AUTOSAR XML (schema 4-0-3)
standard types defined: Std_ReturnType
package /Csm/CompuMethods
  compu method Csm_ConfigIdTypeValues: 0=HaeAdvSeedKey_L9_Id, 1=HaeSha1_Id, 2=HaeSha256_Id, 0=HaeHmacSha256Generate_Id, 0=HaeHmacSha256Verify_Id, 0=HaeHsmPseudoRandomGenerate_L9_Id, 2=HaePseudoRandomGenerate_Id, 1=HaePseudoRandomGenerate_L9_Id, 1=HaePseudoRandomSeed_Id, 0=HaePseudoRandomSeed_L9_Id, 0=HaePkcs1V15Sha256Generate_Id, 0=HaeAesEcbDecrypt_Id, 0=HaeAesEcbEncrypt_Id, 0=HaeAesCbcDecrypt_Id, 1=HaeAesCtrDecrypt_Id, 0=HaeAesCbcEncrypt_Id, 1=HaeAesCtrEncrypt_Id
package /Csm/ImplementationDataTypes
  impl type Csm_AlignType: implementation-data-type=uint8
  impl type Csm_ConfigIdType: implementation-data-type=uint16
  impl type Csm_VerifyResultType: compu {0=CSM_E_VER_OK, 1=CSM_E_VER_NOT_OK}, implementation-data-type=uint8
package /Csm/ArrayTypes
  20 x impl type, all with category=ARRAY:
    HashDataBuffer
      element HashDataBufferElement: array-size=8, array-size-semantics=FIXED-SIZE, implementation-data-type=uint8
    HashResultBuffer
      element HashResultBufferElement: array-size=8, array-size-semantics=FIXED-SIZE, implementation-data-type=uint8
    MacGenerateDataBuffer
      element MacGenerateDataBufferElement: array-size=1, array-size-semantics=FIXED-SIZE, implementation-data-type=uint8
    MacGenerateResultBuffer
      element MacGenerateResultBufferElement: array-size=32, array-size-semantics=FIXED-SIZE, implementation-data-type=uint8
    MacVerifyCompareBuffer
      element MacVerifyCompareBufferElement: array-size=32, array-size-semantics=FIXED-SIZE, implementation-data-type=uint8
    MacVerifyDataBuffer
      element MacVerifyDataBufferElement: array-size=1, array-size-semantics=FIXED-SIZE, implementation-data-type=uint8
    RandomGenerateResultBuffer
      element RandomGenerateResultBufferElement: array-size=8, array-size-semantics=FIXED-SIZE, implementation-data-type=uint8
    RandomSeedDataBuffer
      element RandomSeedDataBufferElement: array-size=16, array-size-semantics=FIXED-SIZE, implementation-data-type=uint8
    SignatureGenerateDataBuffer
      element SignatureGenerateDataBufferElement: array-size=1, array-size-semantics=FIXED-SIZE, implementation-data-type=uint8
    SignatureGenerateResultBuffer
      element SignatureGenerateResultBufferElement: array-size=256, array-size-semantics=FIXED-SIZE, implementation-data-type=uint8
    SymBlockDecryptDataBuffer
      element SymBlockDecryptDataBufferElement: array-size=1, array-size-semantics=FIXED-SIZE, implementation-data-type=uint8
    SymBlockDecryptResultBuffer
      element SymBlockDecryptResultBufferElement: array-size=1, array-size-semantics=FIXED-SIZE, implementation-data-type=uint8
    SymBlockEncryptDataBuffer
      element SymBlockEncryptDataBufferElement: array-size=1, array-size-semantics=FIXED-SIZE, implementation-data-type=uint8
    SymBlockEncryptResultBuffer
      element SymBlockEncryptResultBufferElement: array-size=1, array-size-semantics=FIXED-SIZE, implementation-data-type=uint8
    SymDecryptDataBuffer
      element SymDecryptDataBufferElement: array-size=1, array-size-semantics=FIXED-SIZE, implementation-data-type=uint8
    SymDecryptInitVectorBuffer
      element SymDecryptInitVectorBufferElement: array-size=16, array-size-semantics=FIXED-SIZE, implementation-data-type=uint8
    SymDecryptResultBuffer
      element SymDecryptResultBufferElement: array-size=1, array-size-semantics=FIXED-SIZE, implementation-data-type=uint8
    SymEncryptDataBuffer
      element SymEncryptDataBufferElement: array-size=1, array-size-semantics=FIXED-SIZE, implementation-data-type=uint8
    SymEncryptInitVectorBuffer
      element SymEncryptInitVectorBufferElement: array-size=16, array-size-semantics=FIXED-SIZE, implementation-data-type=uint8
    SymEncryptResultBuffer
      element SymEncryptResultBufferElement: array-size=1, array-size-semantics=FIXED-SIZE, implementation-data-type=uint8
package /Csm/RecordTypes
  impl type Csm_AsymPrivateKeyType: category=STRUCTURE
    element length: implementation-data-type=uint32
    element data: category=ARRAY, array-size-semantics=FIXED-SIZE
      element data_element: array-size=512, array-size-semantics=FIXED-SIZE, implementation-data-type=Csm_AlignType
  impl type Csm_SymKeyType: category=STRUCTURE
    element length: implementation-data-type=uint32
    element data: category=ARRAY, array-size-semantics=FIXED-SIZE
      element data_element: array-size=16, array-size-semantics=FIXED-SIZE, implementation-data-type=Csm_AlignType
package /Csm/ClientServerInterfaces
  11 x client server interface, all with is-service=true, service-kind=CRYPTO-SERVICE-MANAGER:
    CsmHash
      operation HashStart: possible-error=[CsmHash/E_NOT_OK, CsmHash/CSM_E_BUSY]
      operation HashUpdate: possible-error=[CsmHash/E_NOT_OK, CsmHash/CSM_E_BUSY]
        arg dataBuffer: type=HashDataBuffer, direction=IN
        arg dataLength: type=uint32, direction=IN
      operation HashFinish: possible-error=[CsmHash/E_NOT_OK, CsmHash/CSM_E_BUSY, CsmHash/CSM_E_SMALL_BUFFER]
        arg resultBuffer: type=HashResultBuffer, direction=OUT
        arg resultLength: type=uint32, direction=INOUT
        arg TruncationIsAllowed: type=boolean, direction=IN
      error E_NOT_OK: error-code=1
      error CSM_E_BUSY: error-code=2
      error CSM_E_SMALL_BUFFER: error-code=3
    CsmMacGenerate
      operation MacGenerateStart: possible-error=[CsmMacGenerate/E_NOT_OK, CsmMacGenerate/CSM_E_BUSY]
        arg key: type=Csm_SymKeyType, direction=IN
      operation MacGenerateUpdate: possible-error=[CsmMacGenerate/E_NOT_OK, CsmMacGenerate/CSM_E_BUSY]
        arg dataBuffer: type=MacGenerateDataBuffer, direction=IN
        arg dataLength: type=uint32, direction=IN
      operation MacGenerateFinish: possible-error=[CsmMacGenerate/E_NOT_OK, CsmMacGenerate/CSM_E_BUSY, CsmMacGenerate/CSM_E_SMALL_BUFFER]
        arg resultBuffer: type=MacGenerateResultBuffer, direction=OUT
        arg resultLength: type=uint32, direction=INOUT
        arg TruncationIsAllowed: type=boolean, direction=IN
      error E_NOT_OK: error-code=1
      error CSM_E_BUSY: error-code=2
      error CSM_E_SMALL_BUFFER: error-code=3
    CsmMacVerify
      operation MacVerifyStart: possible-error=[CsmMacVerify/E_NOT_OK, CsmMacVerify/CSM_E_BUSY]
        arg key: type=Csm_SymKeyType, direction=IN
      operation MacVerifyUpdate: possible-error=[CsmMacVerify/E_NOT_OK, CsmMacVerify/CSM_E_BUSY]
        arg dataBuffer: type=MacVerifyDataBuffer, direction=IN
        arg dataLength: type=uint32, direction=IN
      operation MacVerifyFinish: possible-error=[CsmMacVerify/E_NOT_OK, CsmMacVerify/CSM_E_BUSY]
        arg MacBuffer: type=MacVerifyCompareBuffer, direction=IN
        arg MacLength: type=uint32, direction=IN
        arg resultBuffer: type=Csm_VerifyResultType, direction=OUT
      error E_NOT_OK: error-code=1
      error CSM_E_BUSY: error-code=2
    CsmRandomGenerate
      operation RandomGenerate: possible-error=[CsmRandomGenerate/E_NOT_OK, CsmRandomGenerate/CSM_E_BUSY, CSM_E_ENTROPY_EXHAUSTION]
        arg resultBuffer: type=RandomGenerateResultBuffer, direction=OUT
        arg resultLength: type=uint32, direction=IN
      error E_NOT_OK: error-code=1
      error CSM_E_BUSY: error-code=2
      error CSM_E_ENTROPY_EXHAUSTION: error-code=4
    CsmRandomSeed
      operation RandomSeedStart: possible-error=[CsmRandomSeed/E_NOT_OK, CsmRandomSeed/CSM_E_BUSY]
      operation RandomSeedUpdate: possible-error=[CsmRandomSeed/E_NOT_OK, CsmRandomSeed/CSM_E_BUSY]
        arg seedBuffer: type=RandomSeedDataBuffer, direction=IN
        arg seedLength: type=uint32, direction=IN
      operation RandomSeedFinish: possible-error=[CsmRandomSeed/E_NOT_OK, CsmRandomSeed/CSM_E_BUSY]
      error E_NOT_OK: error-code=1
      error CSM_E_BUSY: error-code=2
    CsmSignatureGenerate
      operation SignatureGenerateStart: possible-error=[CsmSignatureGenerate/E_NOT_OK, CsmSignatureGenerate/CSM_E_BUSY]
        arg key: type=Csm_AsymPrivateKeyType, direction=IN
      operation SignatureGenerateUpdate: possible-error=[CsmSignatureGenerate/E_NOT_OK, CsmSignatureGenerate/CSM_E_BUSY, CsmSignatureGenerate/CSM_E_SMALL_BUFFER]
        arg dataBuffer: type=SignatureGenerateDataBuffer, direction=IN
        arg dataLength: type=uint32, direction=IN
      operation SignatureGenerateFinish: possible-error=[CsmSignatureGenerate/E_NOT_OK, CsmSignatureGenerate/CSM_E_BUSY, CsmSignatureGenerate/CSM_E_SMALL_BUFFER]
        arg resultBuffer: type=SignatureGenerateResultBuffer, direction=OUT
        arg resultLength: type=uint32, direction=INOUT
      error E_NOT_OK: error-code=1
      error CSM_E_BUSY: error-code=2
      error CSM_E_SMALL_BUFFER: error-code=3
    CsmSymBlockDecrypt
      operation SymBlockDecryptStart: possible-error=[CsmSymBlockDecrypt/E_NOT_OK, CsmSymBlockDecrypt/CSM_E_BUSY]
        arg key: type=Csm_SymKeyType, direction=IN
      operation SymBlockDecryptUpdate: possible-error=[CsmSymBlockDecrypt/E_NOT_OK, CsmSymBlockDecrypt/CSM_E_BUSY, CsmSymBlockDecrypt/CSM_E_SMALL_BUFFER]
        4 x arg:
          cipherTextBuffer: type=SymBlockDecryptDataBuffer, direction=IN
          cipherTextLength: type=uint32, direction=IN
          plainTextBuffer: type=SymBlockDecryptResultBuffer, direction=OUT
          plainTextLength: type=uint32, direction=INOUT
      operation SymBlockDecryptFinish: possible-error=[CsmSymBlockDecrypt/E_NOT_OK, CsmSymBlockDecrypt/CSM_E_BUSY]
      error E_NOT_OK: error-code=1
      error CSM_E_BUSY: error-code=2
      error CSM_E_SMALL_BUFFER: error-code=3
    CsmSymBlockEncrypt
      operation SymBlockEncryptStart: possible-error=[CsmSymBlockEncrypt/E_NOT_OK, CsmSymBlockEncrypt/CSM_E_BUSY]
        arg key: type=Csm_SymKeyType, direction=IN
      operation SymBlockEncryptUpdate: possible-error=[CsmSymBlockEncrypt/E_NOT_OK, CsmSymBlockEncrypt/CSM_E_BUSY, CsmSymBlockEncrypt/CSM_E_SMALL_BUFFER]
        4 x arg:
          plainTextBuffer: type=SymBlockEncryptDataBuffer, direction=IN
          plainTextLength: type=uint32, direction=IN
          cipherTextBuffer: type=SymBlockEncryptResultBuffer, direction=OUT
          cipherTextLength: type=uint32, direction=INOUT
      operation SymBlockEncryptFinish: possible-error=[CsmSymBlockEncrypt/E_NOT_OK, CsmSymBlockEncrypt/CSM_E_BUSY]
      error E_NOT_OK: error-code=1
      error CSM_E_BUSY: error-code=2
      error CSM_E_SMALL_BUFFER: error-code=3
    CsmSymDecrypt
      operation SymDecryptStart: possible-error=[CsmSymDecrypt/E_NOT_OK, CsmSymDecrypt/CSM_E_BUSY]
        arg key: type=Csm_SymKeyType, direction=IN
        arg InitVectorBuffer: type=SymEncryptInitVectorBuffer, direction=IN
        arg InitVectorLength: type=uint32, direction=IN
      operation SymDecryptUpdate: possible-error=[CsmSymDecrypt/E_NOT_OK, CsmSymDecrypt/CSM_E_BUSY, CsmSymDecrypt/CSM_E_SMALL_BUFFER]
        4 x arg:
          cipherTextBuffer: type=SymDecryptDataBuffer, direction=IN
          cipherTextLength: type=uint32, direction=IN
          plainTextBuffer: type=SymDecryptResultBuffer, direction=OUT
          plainTextLength: type=uint32, direction=INOUT
      operation SymDecryptFinish: possible-error=[CsmSymDecrypt/E_NOT_OK, CsmSymDecrypt/CSM_E_BUSY, CsmSymDecrypt/CSM_E_SMALL_BUFFER]
        arg plainTextBuffer: type=SymDecryptResultBuffer, direction=OUT
        arg plainTextLength: type=uint32, direction=INOUT
      error E_NOT_OK: error-code=1
      error CSM_E_BUSY: error-code=2
      error CSM_E_SMALL_BUFFER: error-code=3
    CsmSymEncrypt
      operation SymEncryptStart: possible-error=[CsmSymEncrypt/E_NOT_OK, CsmSymEncrypt/CSM_E_BUSY]
        arg key: type=Csm_SymKeyType, direction=IN
        arg InitVectorBuffer: type=SymEncryptInitVectorBuffer, direction=IN
        arg InitVectorLength: type=uint32, direction=IN
      operation SymEncryptUpdate: possible-error=[CsmSymEncrypt/E_NOT_OK, CsmSymEncrypt/CSM_E_BUSY, CsmSymEncrypt/CSM_E_SMALL_BUFFER]
        4 x arg:
          plainTextBuffer: type=SymEncryptDataBuffer, direction=IN
          plainTextLength: type=uint32, direction=IN
          cipherTextBuffer: type=SymEncryptResultBuffer, direction=OUT
          cipherTextLength: type=uint32, direction=INOUT
      operation SymEncryptFinish: possible-error=[CsmSymEncrypt/E_NOT_OK, CsmSymEncrypt/CSM_E_BUSY, CsmSymEncrypt/CSM_E_SMALL_BUFFER]
        arg cipherTextBuffer: type=SymEncryptResultBuffer, direction=OUT
        arg cipherTextLength: type=uint32, direction=INOUT
      error E_NOT_OK: error-code=1
      error CSM_E_BUSY: error-code=2
      error CSM_E_SMALL_BUFFER: error-code=3
    CsmCallback
      operation JobFinished: possible-error=CsmCallback/E_NOT_OK
        arg retVal: type=Std_ReturnType, direction=IN
      error E_NOT_OK: error-code=1
package /Csm/ServiceSwComponentTypes
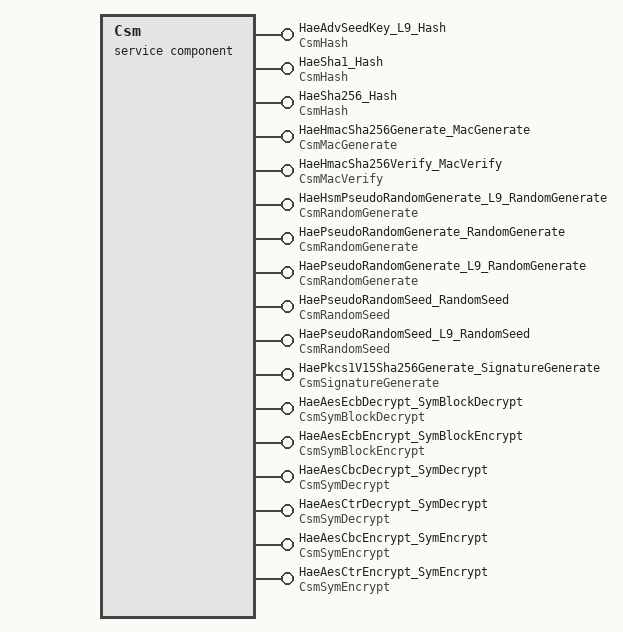
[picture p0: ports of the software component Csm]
  service sw component type Csm
    17 x provide port:
      HaeAdvSeedKey_L9_Hash: provided-interface=CsmHash
        provided-com-specs:
          operation=HashStart, queue-length=1
          operation=HashUpdate, queue-length=1
          operation=HashFinish, queue-length=1
      HaeSha1_Hash: provided-interface=CsmHash
        provided-com-specs:
          operation=HashStart, queue-length=1
          operation=HashUpdate, queue-length=1
          operation=HashFinish, queue-length=1
      HaeSha256_Hash: provided-interface=CsmHash
        provided-com-specs:
          operation=HashStart, queue-length=1
          operation=HashUpdate, queue-length=1
          operation=HashFinish, queue-length=1
      HaeHmacSha256Generate_MacGenerate: provided-interface=CsmMacGenerate
        provided-com-specs:
          operation=MacGenerateStart, queue-length=1
          operation=MacGenerateUpdate, queue-length=1
          operation=MacGenerateFinish, queue-length=1
      HaeHmacSha256Verify_MacVerify: provided-interface=CsmMacVerify
        provided-com-specs:
          operation=MacVerifyStart, queue-length=1
          operation=MacVerifyUpdate, queue-length=1
          operation=MacVerifyFinish, queue-length=1
      HaeHsmPseudoRandomGenerate_L9_RandomGenerate: server-com-spec{operation=RandomGenerate, queue-length=1}, provided-interface=CsmRandomGenerate
      HaePseudoRandomGenerate_RandomGenerate: server-com-spec{operation=RandomGenerate, queue-length=1}, provided-interface=CsmRandomGenerate
      HaePseudoRandomGenerate_L9_RandomGenerate: server-com-spec{operation=RandomGenerate, queue-length=1}, provided-interface=CsmRandomGenerate
      HaePseudoRandomSeed_RandomSeed: provided-interface=CsmRandomSeed
        provided-com-specs:
          operation=RandomSeedStart, queue-length=1
          operation=RandomSeedUpdate, queue-length=1
          operation=RandomSeedFinish, queue-length=1
      HaePseudoRandomSeed_L9_RandomSeed: provided-interface=CsmRandomSeed
        provided-com-specs:
          operation=RandomSeedStart, queue-length=1
          operation=RandomSeedUpdate, queue-length=1
          operation=RandomSeedFinish, queue-length=1
      HaePkcs1V15Sha256Generate_SignatureGenerate: provided-interface=CsmSignatureGenerate
        provided-com-specs:
          operation=SignatureGenerateStart, queue-length=1
          operation=SignatureGenerateUpdate, queue-length=1
          operation=SignatureGenerateFinish, queue-length=1
      HaeAesEcbDecrypt_SymBlockDecrypt: provided-interface=CsmSymBlockDecrypt
        provided-com-specs:
          operation=SymBlockDecryptStart, queue-length=1
          operation=SymBlockDecryptUpdate, queue-length=1
          operation=SymBlockDecryptFinish, queue-length=1
      HaeAesEcbEncrypt_SymBlockEncrypt: provided-interface=CsmSymBlockEncrypt
        provided-com-specs:
          operation=SymBlockEncryptStart, queue-length=1
          operation=SymBlockEncryptUpdate, queue-length=1
          operation=SymBlockEncryptFinish, queue-length=1
      HaeAesCbcDecrypt_SymDecrypt: provided-interface=CsmSymDecrypt
        provided-com-specs:
          operation=SymDecryptStart, queue-length=1
          operation=SymDecryptUpdate, queue-length=1
          operation=SymDecryptFinish, queue-length=1
      HaeAesCtrDecrypt_SymDecrypt: provided-interface=CsmSymDecrypt
        provided-com-specs:
          operation=SymDecryptStart, queue-length=1
          operation=SymDecryptUpdate, queue-length=1
          operation=SymDecryptFinish, queue-length=1
      HaeAesCbcEncrypt_SymEncrypt: provided-interface=CsmSymEncrypt
        provided-com-specs:
          operation=SymEncryptStart, queue-length=1
          operation=SymEncryptUpdate, queue-length=1
          operation=SymEncryptFinish, queue-length=1
      HaeAesCtrEncrypt_SymEncrypt: provided-interface=CsmSymEncrypt
        provided-com-specs:
          operation=SymEncryptStart, queue-length=1
          operation=SymEncryptUpdate, queue-length=1
          operation=SymEncryptFinish, queue-length=1
    behavior CsmInternalBehavior: included-data-type-set=data-type=Csm_VerifyResultType
      45 x operation invoked event:
        OperationInvokedEvent_HaeAdvSeedKey_L9_Hash_HashStart: start-on-event=Csm_HashStart, operation=HaeAdvSeedKey_L9_Hash.HashStart
        OperationInvokedEvent_HaeAdvSeedKey_L9_Hash_HashUpdate: start-on-event=Csm_HashUpdate, operation=HaeAdvSeedKey_L9_Hash.HashUpdate
        OperationInvokedEvent_HaeAdvSeedKey_L9_Hash_HashFinish: start-on-event=Csm_HashFinish, operation=HaeAdvSeedKey_L9_Hash.HashFinish
        OperationInvokedEvent_HaeSha1_Hash_HashStart: start-on-event=Csm_HashStart, operation=HaeSha1_Hash.HashStart
        OperationInvokedEvent_HaeSha1_Hash_HashUpdate: start-on-event=Csm_HashUpdate, operation=HaeSha1_Hash.HashUpdate
        OperationInvokedEvent_HaeSha1_Hash_HashFinish: start-on-event=Csm_HashFinish, operation=HaeSha1_Hash.HashFinish
        OperationInvokedEvent_HaeSha256_Hash_HashStart: start-on-event=Csm_HashStart, operation=HaeSha256_Hash.HashStart
        OperationInvokedEvent_HaeSha256_Hash_HashUpdate: start-on-event=Csm_HashUpdate, operation=HaeSha256_Hash.HashUpdate
        OperationInvokedEvent_HaeSha256_Hash_HashFinish: start-on-event=Csm_HashFinish, operation=HaeSha256_Hash.HashFinish
        OperationInvokedEvent_HaeHmacSha256Generate_MacGenerate_MacGenerateStart: start-on-event=Csm_MacGenerateStart, operation=HaeHmacSha256Generate_MacGenerate.MacGenerateStart
        OperationInvokedEvent_HaeHmacSha256Generate_MacGenerate_MacGenerateUpdate: start-on-event=Csm_MacGenerateUpdate, operation=HaeHmacSha256Generate_MacGenerate.MacGenerateUpdate
        OperationInvokedEvent_HaeHmacSha256Generate_MacGenerate_MacGenerateFinish: start-on-event=Csm_MacGenerateFinish, operation=HaeHmacSha256Generate_MacGenerate.MacGenerateFinish
        OperationInvokedEvent_HaeHmacSha256Verify_MacVerify_MacVerifyStart: start-on-event=Csm_MacVerifyStart, operation=HaeHmacSha256Verify_MacVerify.MacVerifyStart
        OperationInvokedEvent_HaeHmacSha256Verify_MacVerify_MacVerifyUpdate: start-on-event=Csm_MacVerifyUpdate, operation=HaeHmacSha256Verify_MacVerify.MacVerifyUpdate
        OperationInvokedEvent_HaeHmacSha256Verify_MacVerify_MacVerifyFinish: start-on-event=Csm_MacVerifyFinish, operation=HaeHmacSha256Verify_MacVerify.MacVerifyFinish
        OperationInvokedEvent_HaeHsmPseudoRandomGenerate_L9_RandomGenerate_RandomGenerate: start-on-event=Csm_RandomGenerate, operation=HaeHsmPseudoRandomGenerate_L9_RandomGenerate.RandomGenerate
        OperationInvokedEvent_HaePseudoRandomGenerate_RandomGenerate_RandomGenerate: start-on-event=Csm_RandomGenerate, operation=HaePseudoRandomGenerate_RandomGenerate.RandomGenerate
        OperationInvokedEvent_HaePseudoRandomGenerate_L9_RandomGenerate_RandomGenerate: start-on-event=Csm_RandomGenerate, operation=HaePseudoRandomGenerate_L9_RandomGenerate.RandomGenerate
        OperationInvokedEvent_HaePseudoRandomSeed_RandomSeed_RandomSeedStart: start-on-event=Csm_RandomSeedStart, operation=HaePseudoRandomSeed_RandomSeed.RandomSeedStart
        OperationInvokedEvent_HaePseudoRandomSeed_RandomSeed_RandomSeedUpdate: start-on-event=Csm_RandomSeedUpdate, operation=HaePseudoRandomSeed_RandomSeed.RandomSeedUpdate
        OperationInvokedEvent_HaePseudoRandomSeed_RandomSeed_RandomSeedFinish: start-on-event=Csm_RandomSeedFinish, operation=HaePseudoRandomSeed_RandomSeed.RandomSeedFinish
        OperationInvokedEvent_HaePseudoRandomSeed_L9_RandomSeed_RandomSeedStart: start-on-event=Csm_RandomSeedStart, operation=HaePseudoRandomSeed_L9_RandomSeed.RandomSeedStart
        OperationInvokedEvent_HaePseudoRandomSeed_L9_RandomSeed_RandomSeedUpdate: start-on-event=Csm_RandomSeedUpdate, operation=HaePseudoRandomSeed_L9_RandomSeed.RandomSeedUpdate
        OperationInvokedEvent_HaePseudoRandomSeed_L9_RandomSeed_RandomSeedFinish: start-on-event=Csm_RandomSeedFinish, operation=HaePseudoRandomSeed_L9_RandomSeed.RandomSeedFinish
        OperationInvokedEvent_HaePkcs1V15Sha256Generate_SignatureGenerate_SignatureGenerateStart: start-on-event=Csm_SignatureGenerateStart, operation=HaePkcs1V15Sha256Generate_SignatureGenerate.SignatureGenerateStart
        OperationInvokedEvent_HaePkcs1V15Sha256Generate_SignatureGenerate_SignatureGenerateUpdate: start-on-event=Csm_SignatureGenerateUpdate, operation=HaePkcs1V15Sha256Generate_SignatureGenerate.SignatureGenerateUpdate
        OperationInvokedEvent_HaePkcs1V15Sha256Generate_SignatureGenerate_SignatureGenerateFinish: start-on-event=Csm_SignatureGenerateFinish, operation=HaePkcs1V15Sha256Generate_SignatureGenerate.SignatureGenerateFinish
        OperationInvokedEvent_HaeAesEcbDecrypt_SymBlockDecrypt_SymBlockDecryptStart: start-on-event=Csm_SymBlockDecryptStart, operation=HaeAesEcbDecrypt_SymBlockDecrypt.SymBlockDecryptStart
        OperationInvokedEvent_HaeAesEcbDecrypt_SymBlockDecrypt_SymBlockDecryptUpdate: start-on-event=Csm_SymBlockDecryptUpdate, operation=HaeAesEcbDecrypt_SymBlockDecrypt.SymBlockDecryptUpdate
        OperationInvokedEvent_HaeAesEcbDecrypt_SymBlockDecrypt_SymBlockDecryptFinish: start-on-event=Csm_SymBlockDecryptFinish, operation=HaeAesEcbDecrypt_SymBlockDecrypt.SymBlockDecryptFinish
        OperationInvokedEvent_HaeAesEcbEncrypt_SymBlockEncrypt_SymBlockEncryptStart: start-on-event=Csm_SymBlockEncryptStart, operation=HaeAesEcbEncrypt_SymBlockEncrypt.SymBlockEncryptStart
        OperationInvokedEvent_HaeAesEcbEncrypt_SymBlockEncrypt_SymBlockEncryptUpdate: start-on-event=Csm_SymBlockEncryptUpdate, operation=HaeAesEcbEncrypt_SymBlockEncrypt.SymBlockEncryptUpdate
        OperationInvokedEvent_HaeAesEcbEncrypt_SymBlockEncrypt_SymBlockEncryptFinish: start-on-event=Csm_SymBlockEncryptFinish, operation=HaeAesEcbEncrypt_SymBlockEncrypt.SymBlockEncryptFinish
        OperationInvokedEvent_HaeAesCbcDecrypt_SymDecrypt_SymDecryptStart: start-on-event=Csm_SymDecryptStart, operation=HaeAesCbcDecrypt_SymDecrypt.SymDecryptStart
        OperationInvokedEvent_HaeAesCbcDecrypt_SymDecrypt_SymDecryptUpdate: start-on-event=Csm_SymDecryptUpdate, operation=HaeAesCbcDecrypt_SymDecrypt.SymDecryptUpdate
        OperationInvokedEvent_HaeAesCbcDecrypt_SymDecrypt_SymDecryptFinish: start-on-event=Csm_SymDecryptFinish, operation=HaeAesCbcDecrypt_SymDecrypt.SymDecryptFinish
        OperationInvokedEvent_HaeAesCtrDecrypt_SymDecrypt_SymDecryptStart: start-on-event=Csm_SymDecryptStart, operation=HaeAesCtrDecrypt_SymDecrypt.SymDecryptStart
        OperationInvokedEvent_HaeAesCtrDecrypt_SymDecrypt_SymDecryptUpdate: start-on-event=Csm_SymDecryptUpdate, operation=HaeAesCtrDecrypt_SymDecrypt.SymDecryptUpdate
        OperationInvokedEvent_HaeAesCtrDecrypt_SymDecrypt_SymDecryptFinish: start-on-event=Csm_SymDecryptFinish, operation=HaeAesCtrDecrypt_SymDecrypt.SymDecryptFinish
        OperationInvokedEvent_HaeAesCbcEncrypt_SymEncrypt_SymEncryptStart: start-on-event=Csm_SymEncryptStart, operation=HaeAesCbcEncrypt_SymEncrypt.SymEncryptStart
        OperationInvokedEvent_HaeAesCbcEncrypt_SymEncrypt_SymEncryptUpdate: start-on-event=Csm_SymEncryptUpdate, operation=HaeAesCbcEncrypt_SymEncrypt.SymEncryptUpdate
        OperationInvokedEvent_HaeAesCbcEncrypt_SymEncrypt_SymEncryptFinish: start-on-event=Csm_SymEncryptFinish, operation=HaeAesCbcEncrypt_SymEncrypt.SymEncryptFinish
        OperationInvokedEvent_HaeAesCtrEncrypt_SymEncrypt_SymEncryptStart: start-on-event=Csm_SymEncryptStart, operation=HaeAesCtrEncrypt_SymEncrypt.SymEncryptStart
        OperationInvokedEvent_HaeAesCtrEncrypt_SymEncrypt_SymEncryptUpdate: start-on-event=Csm_SymEncryptUpdate, operation=HaeAesCtrEncrypt_SymEncrypt.SymEncryptUpdate
        OperationInvokedEvent_HaeAesCtrEncrypt_SymEncrypt_SymEncryptFinish: start-on-event=Csm_SymEncryptFinish, operation=HaeAesCtrEncrypt_SymEncrypt.SymEncryptFinish
      port-api-options:
        {enable-take-address=false, indirect-api=false, port-defined-argument-value{value=HaeAdvSeedKey_L9_Hash_Id:0, value-type=Csm_ConfigIdType}, port=HaeAdvSeedKey_L9_Hash}
        {enable-take-address=false, indirect-api=false, port-defined-argument-value{value=HaeSha1_Hash_Id:1, value-type=Csm_ConfigIdType}, port=HaeSha1_Hash}
        {enable-take-address=false, indirect-api=false, port-defined-argument-value{value=HaeSha256_Hash_Id:2, value-type=Csm_ConfigIdType}, port=HaeSha256_Hash}
        {enable-take-address=false, indirect-api=false, port-defined-argument-value{value=HaeHmacSha256Generate_MacGenerate_Id:0, value-type=Csm_ConfigIdType}, port=HaeHmacSha256Generate_MacGenerate}
        {enable-take-address=false, indirect-api=false, port-defined-argument-value{value=HaeHmacSha256Verify_MacVerify_Id:0, value-type=Csm_ConfigIdType}, port=HaeHmacSha256Verify_MacVerify}
        {enable-take-address=false, indirect-api=false, port-defined-argument-value{value=HaeHsmPseudoRandomGenerate_L9_RandomGenerate_Id:0, value-type=Csm_ConfigIdType}, port=HaeHsmPseudoRandomGenerate_L9_RandomGenerate}
        {enable-take-address=false, indirect-api=false, port-defined-argument-value{value=HaePseudoRandomGenerate_RandomGenerate_Id:2, value-type=Csm_ConfigIdType}, port=HaePseudoRandomGenerate_RandomGenerate}
        {enable-take-address=false, indirect-api=false, port-defined-argument-value{value=HaePseudoRandomGenerate_L9_RandomGenerate_Id:1, value-type=Csm_ConfigIdType}, port=HaePseudoRandomGenerate_L9_RandomGenerate}
        {enable-take-address=false, indirect-api=false, port-defined-argument-value{value=HaePseudoRandomSeed_RandomSeed_Id:1, value-type=Csm_ConfigIdType}, port=HaePseudoRandomSeed_RandomSeed}
        {enable-take-address=false, indirect-api=false, port-defined-argument-value{value=HaePseudoRandomSeed_L9_RandomSeed_Id:0, value-type=Csm_ConfigIdType}, port=HaePseudoRandomSeed_L9_RandomSeed}
        {enable-take-address=false, indirect-api=false, port-defined-argument-value{value=HaePkcs1V15Sha256Generate_SignatureGenerate_Id:0, value-type=Csm_ConfigIdType}, port=HaePkcs1V15Sha256Generate_SignatureGenerate}
        {enable-take-address=false, indirect-api=false, port-defined-argument-value{value=HaeAesEcbDecrypt_SymBlockDecrypt_Id:0, value-type=Csm_ConfigIdType}, port=HaeAesEcbDecrypt_SymBlockDecrypt}
        {enable-take-address=false, indirect-api=false, port-defined-argument-value{value=HaeAesEcbEncrypt_SymBlockEncrypt_Id:0, value-type=Csm_ConfigIdType}, port=HaeAesEcbEncrypt_SymBlockEncrypt}
        {enable-take-address=false, indirect-api=false, port-defined-argument-value{value=HaeAesCbcDecrypt_SymDecrypt_Id:0, value-type=Csm_ConfigIdType}, port=HaeAesCbcDecrypt_SymDecrypt}
        {enable-take-address=false, indirect-api=false, port-defined-argument-value{value=HaeAesCtrDecrypt_SymDecrypt_Id:1, value-type=Csm_ConfigIdType}, port=HaeAesCtrDecrypt_SymDecrypt}
        {enable-take-address=false, indirect-api=false, port-defined-argument-value{value=HaeAesCbcEncrypt_SymEncrypt_Id:0, value-type=Csm_ConfigIdType}, port=HaeAesCbcEncrypt_SymEncrypt}
        {enable-take-address=false, indirect-api=false, port-defined-argument-value{value=HaeAesCtrEncrypt_SymEncrypt_Id:1, value-type=Csm_ConfigIdType}, port=HaeAesCtrEncrypt_SymEncrypt}
      28 x runnable, all with can-be-invoked-concurrently=true:
        Csm_HashStart
        Csm_HashUpdate
        Csm_HashFinish
        Csm_MacGenerateStart
        Csm_MacGenerateUpdate
        Csm_MacGenerateFinish
        Csm_MacVerifyStart
        Csm_MacVerifyUpdate
        Csm_MacVerifyFinish
        Csm_RandomGenerate
        Csm_RandomSeedStart
        Csm_RandomSeedUpdate
        Csm_RandomSeedFinish
        Csm_SignatureGenerateStart
        Csm_SignatureGenerateUpdate
        Csm_SignatureGenerateFinish
        Csm_SymBlockDecryptStart
        Csm_SymBlockDecryptUpdate
        Csm_SymBlockDecryptFinish
        Csm_SymBlockEncryptStart
        Csm_SymBlockEncryptUpdate
        Csm_SymBlockEncryptFinish
        Csm_SymDecryptStart
        Csm_SymDecryptUpdate
        Csm_SymDecryptFinish
        Csm_SymEncryptStart
        Csm_SymEncryptUpdate
        Csm_SymEncryptFinish
  swc bsw mapping SwcBswMapping_Csm: bsw-behavior=BswInternalBehavior_Csm, swc-behavior=CsmInternalBehavior
    runnable-mappings:
      bsw-entity=BswCE_Csm_HashStart, swc-runnable=Csm_HashStart
      bsw-entity=BswCE_Csm_HashUpdate, swc-runnable=Csm_HashUpdate
      bsw-entity=BswCE_Csm_HashFinish, swc-runnable=Csm_HashFinish
      bsw-entity=BswCE_Csm_MacGenerateStart, swc-runnable=Csm_MacGenerateStart
      bsw-entity=BswCE_Csm_MacGenerateUpdate, swc-runnable=Csm_MacGenerateUpdate
      bsw-entity=BswCE_Csm_MacGenerateFinish, swc-runnable=Csm_MacGenerateFinish
      bsw-entity=BswCE_Csm_MacVerifyStart, swc-runnable=Csm_MacVerifyStart
      bsw-entity=BswCE_Csm_MacVerifyUpdate, swc-runnable=Csm_MacVerifyUpdate
      bsw-entity=BswCE_Csm_MacVerifyFinish, swc-runnable=Csm_MacVerifyFinish
      bsw-entity=BswCE_Csm_RandomGenerate, swc-runnable=Csm_RandomGenerate
      bsw-entity=BswCE_Csm_RandomSeedStart, swc-runnable=Csm_RandomSeedStart
      bsw-entity=BswCE_Csm_RandomSeedUpdate, swc-runnable=Csm_RandomSeedUpdate
      bsw-entity=BswCE_Csm_RandomSeedFinish, swc-runnable=Csm_RandomSeedFinish
      bsw-entity=BswCE_Csm_SignatureGenerateStart, swc-runnable=Csm_SignatureGenerateStart
      bsw-entity=BswCE_Csm_SignatureGenerateUpdate, swc-runnable=Csm_SignatureGenerateUpdate
      bsw-entity=BswCE_Csm_SignatureGenerateFinish, swc-runnable=Csm_SignatureGenerateFinish
      bsw-entity=BswCE_Csm_SymBlockDecryptStart, swc-runnable=Csm_SymBlockDecryptStart
      bsw-entity=BswCE_Csm_SymBlockDecryptUpdate, swc-runnable=Csm_SymBlockDecryptUpdate
      bsw-entity=BswCE_Csm_SymBlockDecryptFinish, swc-runnable=Csm_SymBlockDecryptFinish
      bsw-entity=BswCE_Csm_SymBlockEncryptStart, swc-runnable=Csm_SymBlockEncryptStart
      bsw-entity=BswCE_Csm_SymBlockEncryptUpdate, swc-runnable=Csm_SymBlockEncryptUpdate
      bsw-entity=BswCE_Csm_SymBlockEncryptFinish, swc-runnable=Csm_SymBlockEncryptFinish
      bsw-entity=BswCE_Csm_SymDecryptStart, swc-runnable=Csm_SymDecryptStart
      bsw-entity=BswCE_Csm_SymDecryptUpdate, swc-runnable=Csm_SymDecryptUpdate
      bsw-entity=BswCE_Csm_SymDecryptFinish, swc-runnable=Csm_SymDecryptFinish
      bsw-entity=BswCE_Csm_SymEncryptStart, swc-runnable=Csm_SymEncryptStart
      bsw-entity=BswCE_Csm_SymEncryptUpdate, swc-runnable=Csm_SymEncryptUpdate
      bsw-entity=BswCE_Csm_SymEncryptFinish, swc-runnable=Csm_SymEncryptFinish
  swc implementation SwcImplementation_Csm: swc-bsw-mapping=SwcBswMapping_Csm, behavior=CsmInternalBehavior
